# MK81F25615 register map
Vendor: Freescale Semiconductor, Inc.; Series: Kinetis_K; File version: 1.6
CPU: CM4 r0p1, little endian, no MPU, FPU, VTOR, 4 interrupt priority bits
Registers are 32-bit, read-write, reset 0x0 unless marked. A register's access mark holds for its fields unless they carry their own. Offsets are from the block's base; [hi:lo] are bit positions; {n}, {i} and the like mark numbered series; 'fields as' and 'values as' point back to an identical list.

## LTC0 — LTC
Base 0x400D1000
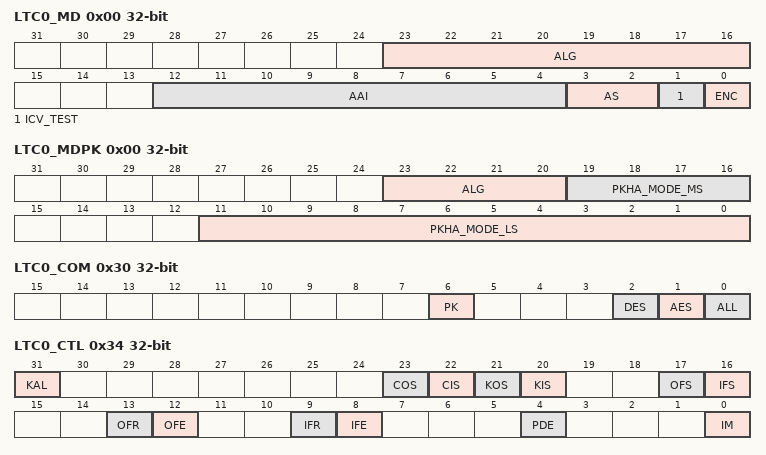
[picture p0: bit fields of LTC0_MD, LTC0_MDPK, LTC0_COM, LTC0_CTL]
0x00 LTC0_MD (LTC0 view) — LTC Mode Register (non-PKHA/non-RNG use)
  [23:16] ALG — Algorithm. This field specifies which algorithm is being selected.
    16=AES; 32=DES; 33=3DES
  [12:4] AAI — Additional Algorithm information
  [3:2] AS — Algorithm State
    0=Update; 1=Initialize; 2=Finalize; 3=Initialize/Finalize
  [1] ICV_TEST — ICV Checking / Test AES fault detection
  [0] ENC — Encrypt/Decrypt. This bit selects encryption or decryption.
    0=Decrypt; 1=Encrypt
0x00 LTC0_MDPK (LTC0 view) — LTC Mode Register (PublicKey)
  [23:20] ALG — Algorithm. This field specifies which algorithm is being selected.
    8=PKHA
  [19:16] PKHA_MODE_MS — PKHA_MODE most-significant 4 bits
  [11:0] PKHA_MODE_LS — PKHA_MODE least significant 12 bits
0x08 LTC0_KS — LTC Key Size Register
  [5:0] KS — Key Size. This is the size of a Key measured in bytes
0x10 LTC0_DS — LTC Data Size Register
  [11:0] DS — Data Size
0x18 LTC0_ICVS — LTC ICV Size Register
  [4:0] ICVS — ICV Size, in Bytes.
0x30 LTC0_COM — LTC Command Register
  [6] PK wo — Reset PKHA. Writing a 1 to this bit resets the Public Key Hardware Accelerator.
    0=Do Not Reset; 1=Reset Public Key Hardware Accelerator
  [2] DES wo — Reset DESA. Writing a 1 to this bit resets the DES Accelerator.
    0=Do Not Reset; 1=Reset DES Accelerator
  [1] AES wo — Reset AESA. Writing a 1 to this bit resets the AES Accelerator core engine.
    0=Do Not Reset; 1=Reset AES Accelerator
  [0] ALL wo — Reset All Internal Logic
    0=Do Not Reset; 1=Reset all CHAs in use by this CCB
0x34 LTC0_CTL — LTC Control Register
  [31] KAL — Key Register Access Lock
    0=Key Register is readable; 1=Key Register is not readable
  [23] COS — Context Register Output Byte Swap
    0=Do Not Byte Swap Data; 1=Byte Swap Data
  [22] CIS — Context Register Input Byte Swap
    0=Do Not Byte Swap Data; 1=Byte Swap Data
  [21] KOS — Key Register Output Byte Swap
    0=Do Not Byte Swap Data; 1=Byte Swap Data
  [20] KIS — Key Register Input Byte Swap
    0=Do Not Byte Swap Data; 1=Byte Swap Data
  [17] OFS — Output FIFO Byte Swap. Byte swap all data that is read from the Onput FIFO.
    0=Do Not Byte Swap Data; 1=Byte Swap Data
  [16] IFS — Input FIFO Byte Swap. Byte swap all data that is written to the Input FIFO.
    0=Do Not Byte Swap Data; 1=Byte Swap Data
  [13] OFR — Output FIFO DMA Request Size
    0=DMA request size is 1 entry; 1=DMA request size is 4 entries
  [12] OFE — Output FIFO DMA Enable.
    0=DMA Request and Done signals disabled for the Output FIFO; 1=DMA Request and Done signals enabled for the Output FIFO
  [9] IFR — Input FIFO DMA Request Size
    values as OFR
  [8] IFE — Input FIFO DMA Enable.
    0=DMA Request and Done signals disabled for the Input FIFO; 1=DMA Request and Done signals enabled for the Input FIFO
  [4] PDE — PKHA Register DMA Enable.
    0=DMA Request and Done signals disabled for the PKHA Registers; 1=DMA Request and Done signals enabled for the PKHA Registers
  [0] IM — Interrupt Mask. Once this bit is set, it can only be cleared by hard reset.
    0=Interrupt not masked; 1=Interrupt masked
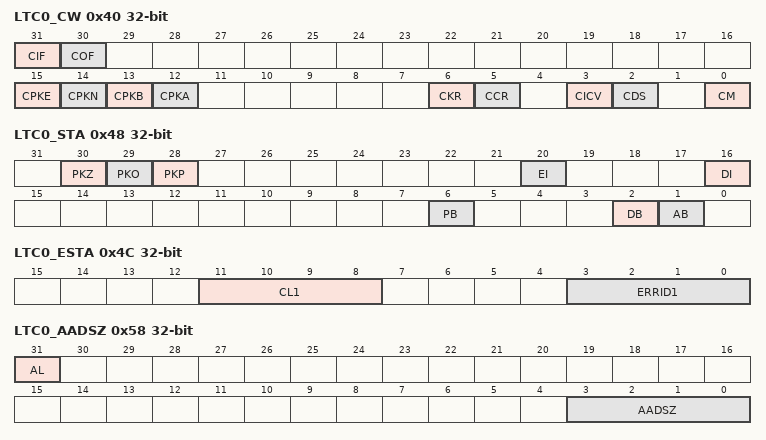
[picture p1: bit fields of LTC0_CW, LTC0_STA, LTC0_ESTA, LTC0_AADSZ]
0x40 LTC0_CW — LTC Clear Written Register
  [31] CIF wo — Clear Input FIFO. Writing a 1 to this bit causes the Input Data FIFO.
  [30] COF wo — Clear Output FIFO. Writing a 1 to this bit causes the Output FIFO to be cleared.
  [15] CPKE wo — Clear the PKHA E Size Register
  [14] CPKN wo — Clear the PKHA N Size Register
  [13] CPKB wo — Clear the PKHA B Size Register
  [12] CPKA wo — Clear the PKHA A Size Register
  [6] CKR wo — Clear the Key Register
  [5] CCR wo — Clear the Context Register. Writing a one to this bit causes the Context Register to be cleared.
  [3] CICV wo — Clear the ICV Size Register. Writing a one to this bit causes the ICV Size Register to be cleared.
  [2] CDS wo — Clear the Data Size Register
  [0] CM wo — Clear the Mode Register. Writing a one to this bit causes the Mode Register to be cleared.
0x48 LTC0_STA — LTC Status Register
  [30] PKZ ro — Public Key Operation is Zero
  [29] PKO ro — Public Key Operation is One
  [28] PKP ro — Public Key is Prime
  [20] EI ro — Error Interrupt
    0=Not Error; 1=Error Interrupt
  [16] DI — Done Interrupt
  [6] PB ro — PKHA Busy
    0=PKHA Idle; 1=PKHA Busy
  [2] DB ro — DESA Busy
    0=DESA Idle; 1=DESA Busy
  [1] AB ro — AESA Busy
    0=AESA Idle; 1=AESA Busy
0x4C LTC0_ESTA ro — LTC Error Status Register
  [11:8] CL1 — algorithms. The algorithms field indicates which algorithm is asserting an error. Others reserved
    0=LTC General Error; 1=AES; 2=DES; 8=Public Key
  [3:0] ERRID1 — Error ID 1
    1=Mode Error; 2=Data Size Error, including PKHA N Register Size Error; 3=Key Size Error, including PKHA E Register Size Error; 4=PKHA A Register Size Error; 5=PKHA B Register Size Error; 6=Data Arrived out of Sequence Error; 7=PKHA Divide by Zero Error; 8=PKHA Modulus Even Error; 9=DES Key Parity Error; 10=ICV Check Failed; 11=Internal Hardware Failure; 12=CCM AAD Size Error (either 1. AAD flag in B0 =1 and no AAD type provided, 2. AAD flag in B0 = 0 and AAD povided, or 3. AAD flag in B0 =1 and not enough AAD provided - expecting more based on AAD size.); 15=Invalid Crypto Engine Selected
0x58 LTC0_AADSZ — LTC AAD Size Register
  [31] AL — AAD Last. Only AAD data will be written into the Input FIFO.
  [3:0] AADSZ — AAD size in Bytes, mod 16.
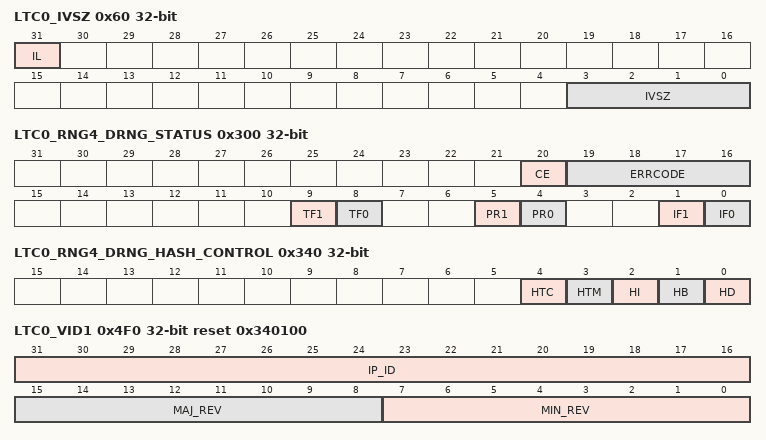
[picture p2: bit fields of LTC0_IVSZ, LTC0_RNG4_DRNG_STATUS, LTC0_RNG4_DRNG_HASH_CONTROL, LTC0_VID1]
0x60 LTC0_IVSZ — LTC IV Size Register
  [31] IL — IV Last. Only IV data will be written into the Input FIFO.
  [3:0] IVSZ — IV size in Bytes, mod 16.
0x68 LTC0_DPAMS wo — LTC DPA Mask Seed Register
  [31:0] DPAMS — Differential Power Analysis Mask Seed
0x80 LTC0_PKASZ — LTC PKHA A Size Register
  [8:0] PKASZ — PKHA A Size. This is the size of the numeric value, in bytes, contained within the PKHA A Register.
0x88 LTC0_PKBSZ — LTC PKHA B Size Register
  [8:0] PKBSZ — PKHA B Size. This is the size of the numeric value, in bytes, contained within the PKHA B Register.
0x90 LTC0_PKNSZ — LTC PKHA N Size Register
  [8:0] PKNSZ — PKHA N Size. This is the size of the numeric value, in bytes, contained within the PKHA N Register.
0x98 LTC0_PKESZ — LTC PKHA E Size Register
  [8:0] PKESZ — PKHA E Size. This is the size of the numeric value, in bytes, contained within the PKHA E Register.
{0x100+4i} LTC0_CTX_{i} (i=0..15) — LTC Context Register
  [31:0] CTX
{0x200+4i} LTC0_KEY_{i} (i=0..7) — LTC Key Registers
  [31:0] KEY
0x300 LTC0_RNG4_DRNG_STATUS ro — LTC RNG4 DRNG Status
  [20] CE — Catastrophic Error
  [19:16] ERRCODE — Error Code
  [9] TF1 — Test Flag State Handle 1. State Handle 1 has been instantiated as a test (deterministic) instance.
  [8] TF0 — Test Flag State Handle 0. State Handle 0 has been instantiated as a test (deterministic) instance.
  [5] PR1 — Prediction Resistance State Handle 1
  [4] PR0 — Prediction Resistance State Handle 0
  [1] IF1 — Instantiated Flag 1. State Handle 1 has been instantiated.
  [0] IF0 — Instantiated Flag 0. State Handle 0 has been instantiated.
0x310 LTC0_RNG4_DRNG_INTERVAL_0 ro — LTC RNG4 DRNG Interval 0 Register
  [31:0] RESINT0 — This read-only register holds the Reseed Interval for State Handle 0.
0x314 LTC0_RNG4_DRNG_INTERVAL_1 ro — LTC RNG4 DRNG Interval 1 Register
  [31:0] RESINT1 — This read-only register holds the Reseed Interval for State Handle 1.
0x340 LTC0_RNG4_DRNG_HASH_CONTROL — LTC RNG4 DRNG Hash Control Register
  [4] HTC wo — Hashing Test Mode Clear. Writing this bit will take the RNG out of hashing test mode.
  [3] HTM — Hashing Test Mode. Writing this bit will put RNG in Hashing Test Mode.
  [2] HI wo — Hashing Initialize. Writing this bit will initialize the Hashing Engine.
  [1] HB wo — Hashing Begin. Writing this bit will cause the Hashing Engine to begin hashing.
  [0] HD ro — Hashing Done. This bit asserts when the hashing engine is done.
0x344 LTC0_RNG4_DRNG_HASH_DIGEST ro — LTC RNG4 DRNG Hash Digest Register
  [31:0] HASHMD — Hashing Message Digest Register
0x348 LTC0_RNG4_DRNG_DEBUG_BUFFER wo — LTC RNG4 DRNG Debug Buffer
  [31:0] HASHBUF — This write-only register provides access to the internal SHA-256 hashing engine's 64-byte buffer
0x4F0 LTC0_VID1 ro reset 0x340100 — LTC Version ID Register
  [31:16] IP_ID — ID(0x0038).
  [15:8] MAJ_REV — Major revision number(0x01).
  [7:0] MIN_REV — Minor revision number(0x00).
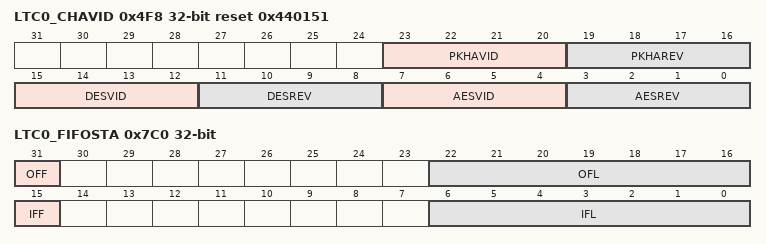
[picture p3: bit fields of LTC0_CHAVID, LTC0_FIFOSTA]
0x4F8 LTC0_CHAVID ro reset 0x440151 — LTC CHA Version ID Register
  [23:20] PKHAVID — PK Version ID(0x4).
  [19:16] PKHAREV — PK Revision Number(0x4).
  [15:12] DESVID — DES Version ID(0x0).
  [11:8] DESREV — DES Revision Number(0x1).
  [7:4] AESVID — AES Version ID(0x5).
  [3:0] AESREV — AES Revision Number(0x1).
0x7C0 LTC0_FIFOSTA ro — LTC FIFO Status Register
  [31] OFF — Output FIFO Full. The Output FIFO is full and should not be written to.
  [22:16] OFL — Output FIFO Level. These bits indicate the current number of entries in the Output FIFO.
  [15] IFF — Input FIFO Full. The Input FIFO is full and should not be written to.
  [6:0] IFL — Input FIFO Level. These bits indicate the current number of entries in the Input FIFO.
0x7E0 LTC0_IFIFO wo — LTC Input Data FIFO
0x7F0 LTC0_OFIFO ro — LTC Output Data FIFO
  [31:0] OFIFO — Output FIFO
{0x800+4i} LTC0_PKA0_{i} (LTC0 view) (i=0..15) — LTC PKHA A0 {i} Register
  [31:0] PKHA_A0 — A0 VALUE
{0x800+4i} LTC0_PKA_{i} (LTC0 view) (i=0..63) — LTC PKHA A {i} Register
{0x840+4i} LTC0_PKA1_{i} (LTC0 view) (i=0..15) — LTC PKHA A1 {i} Register
  [31:0] PKHA_A1 — A1 VALUE
{0x880+4i} LTC0_PKA2_{i} (LTC0 view) (i=0..15) — LTC PKHA A2 {i} Register
  [31:0] PKHA_A2 — A2 VALUE
{0x8C0+4i} LTC0_PKA3_{i} (LTC0 view) (i=0..15) — LTC PKHA A3 {i} Register
  [31:0] PKHA_A3 — A3 VALUE
{0xA00+4i} LTC0_PKB0_{i} (LTC0 view) (i=0..15) — LTC PKHA B0 {i} Register
  [31:0] PKHA_B0 — B0 VALUE
{0xA00+4i} LTC0_PKB_{i} (LTC0 view) (i=0..63) — LTC PKHA B {i} Register
{0xA40+4i} LTC0_PKB1_{i} (LTC0 view) (i=0..15) — LTC PKHA B1 {i} Register
  [31:0] PKHA_B1 — B1 VALUE
{0xA80+4i} LTC0_PKB2_{i} (LTC0 view) (i=0..15) — LTC PKHA B2 {i} Register
  [31:0] PKHA_B2 — B2 VALUE
{0xAC0+4i} LTC0_PKB3_{i} (LTC0 view) (i=0..15) — LTC PKHA B3 {i} Register
  [31:0] PKHA_B3 — B3 VALUE
{0xC00+4i} LTC0_PKN0_{i} (LTC0 view) (i=0..15) — LTC PKHA N0 {i} Register
  [31:0] PKHA_N0 — N0 VALUE
{0xC00+4i} LTC0_PKN_{i} (LTC0 view) (i=0..63) — LTC PKHA N {i} Register
{0xC40+4i} LTC0_PKN1_{i} (LTC0 view) (i=0..15) — LTC PKHA N1 {i} Register
  [31:0] PKHA_N1 — N1 VALUE
{0xC80+4i} LTC0_PKN2_{i} (LTC0 view) (i=0..15) — LTC PKHA N2 {i} Register
  [31:0] PKHA_N2 — N2 VALUE
{0xCC0+4i} LTC0_PKN3_{i} (LTC0 view) (i=0..15) — LTC PKHA N3 {i} Register
  [31:0] PKHA_N3 — N3 VALUE
{0xE00+4i} LTC0_PKE0_{i} (LTC0 view) (i=0..15) — LTC PKHA E0 {i} Register
  [31:0] PKHA_E0 — E0 VALUE
{0xE00+4i} LTC0_PKE_{i} (LTC0 view) (i=0..63) — LTC PKHA E {i} Register
{0xE40+4i} LTC0_PKE1_{i} (LTC0 view) (i=0..15) — LTC PKHA E1 {i} Register
  [31:0] PKHA_E1 — E1 VALUE
{0xE80+4i} LTC0_PKE2_{i} (LTC0 view) (i=0..15) — LTC PKHA E2 {i} Register
  [31:0] PKHA_E2 — E2 VALUE
{0xEC0+4i} LTC0_PKE3_{i} (LTC0 view) (i=0..15) — LTC PKHA E3 {i} Register
  [31:0] PKHA_E3 — E3 VALUE
